# psoc63 register map
Vendor: Cypress Semiconductor; Series: psoc63; File version: 1.0
CPU: CM4 r0p1, little endian, MPU, FPU, VTOR, 3 interrupt priority bits
Registers are 32-bit, read-write, reset 0x0 unless marked. A register's access mark holds for its fields unless they carry their own. Offsets are from the block's base; [hi:lo] are bit positions; lines under a group give offsets from that group; {n}, {i} and the like mark numbered series; 'fields as' and 'values as' point back to an identical list.

## FLASHC — Flash controller
Base 0x40250000
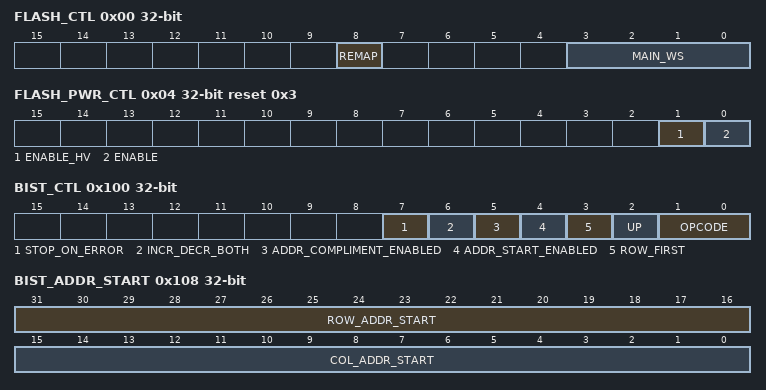
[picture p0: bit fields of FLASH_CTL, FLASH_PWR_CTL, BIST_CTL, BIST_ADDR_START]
0x00 FLASH_CTL — Control
  [8] REMAP — Specifies remapping of FLASH macro main region. '0': No remapping. '1': Remapping. The highest address bit of the FLASH main region is inverted. This effectively remaps the location of FLASH main region physical sectors in the logical address space. In other words, the higher half physical sectors are swapped with the lower half physical sectors. Note: remapping only affects reading of the FLASH main region (over the R interface). It does NOT affect programming/erasing of the FLASH memory region (over the C interface). E.g., for a 512 KB / 4 Mb main region, the logical address space ranges from [0x1000:0000, 0x1007:ffff] (the highest bit if the FLASH main region is bit 18). The memory has four physical sectors: sectors 0, 1, 2 and 3. If REMAP is '0', the physical regions logical addresses are as follows: - The physical region 0: [0x1000:0000, 0x1001:ffff]. - The physical region 1: [0x1002:0000, 0x1003:ffff]. - The physical region 2: [0x1004:0000, 0x1005:ffff]. - The physical region 3: [0x1006:0000, 0x1007:ffff]. If REMAP is '1', the physical regions logical addresses are as follows: - The physical region 0: [0x1004:0000, 0x1005:ffff]. - The physical region 1: [0x1006:0000, 0x1007:ffff]. - The physical region 2: [0x1000:0000, 0x1001:ffff]. - The physical region 3: [0x1002:0000, 0x1003:ffff]. Note: when the REMAP is changed, SW should invalidate the caches and buffers.
  [3:0] MAIN_WS — FLASH macro main interface wait states: '0': 0 wait states. ... '15': 15 wait states
0x04 FLASH_PWR_CTL reset 0x3 — Flash power control
  [1] ENABLE_HV — Controls 'enable_hv' pin of the Flash memory.
  [0] ENABLE — Controls 'enable' pin of the Flash memory.
0x08 FLASH_CMD — Command
  [0] INV — FLASH cache and buffer invalidation for ALL cache and buffers. SW writes a '1' to clear the cache and buffers. HW sets this field to '0' when the operation is completed. The operation takes a maximum of three clock cycles on the slowest of the clk_slow and clk_fast clocks. The caches' LRU structures are also reset to their default state.
0x100 BIST_CTL — BIST control
  [7] STOP_ON_ERROR — Specifies the BIST to continue indefinitely, regardless of occurrence of errors or not. '0': BIST controller doesn't stop on the data failures, it continues regardless of the errors. '1': BIST controller stops on when the first data failure is encounted.
  [6] INCR_DECR_BOTH — Specifies to generate patterns where both column address and row address are incremented/decremented simultaneously. '0': Generate normal increment/decrement patterns. '1': Generate address patterns with both row and column address changing. Example: With UP = 1 and ROW_FIRST = 0 00_00 01_01 10_10 11_11 00_01 01_10 10_11 11_00 00_10 ...
  [5] ADDR_COMPLIMENT_ENABLED — Specifies to generate address compliment patterns. '0': Generate normal increment/decrement patterns. '1': Generate address patterns which interleaves compliment of previous address in between. Example: The following is an exaple pattern, With UP=1 and ROW_FIRST =0 00_00 11_11 00_01 11_10 00_10 11_01 ...
  [4] ADDR_START_ENABLED — Specifies Flash BIST start addresses: '0': Row and column addresses start with their maximum/minimum values. '1': Row and column addresses start with their values as specified by BIST_ADDR_START. This feature is supported only for simple increment/decrement patterns. It is not supported with address compliment pattern (BIST_CTL.ADDR_COMPLIMENT_ENABLED) or address pattern which increments/decrements both row address and column address (BIST_CTL.INCR_DECR_BOTH) for every read.
  [3] ROW_FIRST — Specifies how the Flash BIST addresses are generated: '0': Column address is incremented/decremented till it reaches its maximum/minimum value. Once it reach its maximum/minimum value, it is set to its mimimum/maximum value and only then is the row address incremented/decremented. '1': Row address is incremented/decremented till it reaches its maximum/minimum value. Once it reach its maximum/minimum value, it is set to its mimimum/maximum value and only then is the column address incremented/decremented.
  [2] UP — Specifies direction in which Flash BIST steps through addresses: ''0': BIST steps through the Flash from the maximum row and column addresses (as specified by a design time configurtion parameter when ADDR_START_ENABLED is '0' and as specified by BIST_ADDR_START when ADDR_START_ENABLED is '1') to the minimum row and column addresses. '1': BIST steps through the Flash from the minimum row and column addresses ('0' when ADDR_START_ENABLED is '0' and as specified by BIST_ADDR_START when ADDR_START_ENABLED is '1') to the maximum row and column addresses.
  [1:0] OPCODE — This field specifies how the data check should be performed after reading the data from Flash memory. '0': Read the Flash and compare the output to BIST_DATA (R0). '1': Read the Flash and compare the output to the binary complement of BIST_DATA (R1). '2': Read the Flash and compare with BIST_DATA[] and compliment of BIST_DATA alternately (R01). The expected data of the first read is BIST_DATA, expected data of the second read is binary compliment of BIST_DATA, third read expected data is BIST_DATA, fourth read expected data is binary compliment of BIST_DATA and so on.
0x104 BIST_CMD — BIST command
  [0] START — 1': Start FLASH BIST. Hardware set this field to '0' when BIST is completed.
0x108 BIST_ADDR_START — BIST address start register
  [31:16] ROW_ADDR_START — Row start address. Useful to apply BIST to a part of an Flash. The value of this field should be in a legal range (a value outside of the legal range has an undefined result, and may lock up the BIST state machine). This legal range is dependent on the number of rows of the SRAM the BIST is applied to (as specified by BIST_CTL.SRAMS_ENABLED). E.g. for a Flash with m columns, the legal range is [0, m-1].
  [15:0] COL_ADDR_START — Column start address. Useful to apply BIST to a part of an Flash. The value of this field should be in a legal range (a value outside of the legal range has an undefined result, and may lock up the BIST state machine). This legal range is dependent on the number of columns of the SRAM the BIST is applied to (as specified by BIST_CTL.SRAMS_ENABLED). E.g. for a Flash with n columns, the legal range is [0, n-1].
{0x10C+4i} BIST_DATA[{i}] (i=0..7) — BIST data register(s)
  [31:0] DATA — BIST data register to store the expected value for data comparison. For a 128-bit Flash memory, there will be 4 BIST_DATA registers to store 128-bit value.
{0x12C+4i} BIST_DATA_ACT[{i}] (i=0..7) ro reset not defined — BIST data actual register(s)
  [31:0] DATA — This field specified the actual Flash data output that caused the BIST failure.
{0x14C+4i} BIST_DATA_EXP[{i}] (i=0..7) ro reset not defined — BIST data expected register(s)
  [31:0] DATA — This field specified the expected Flash data output.
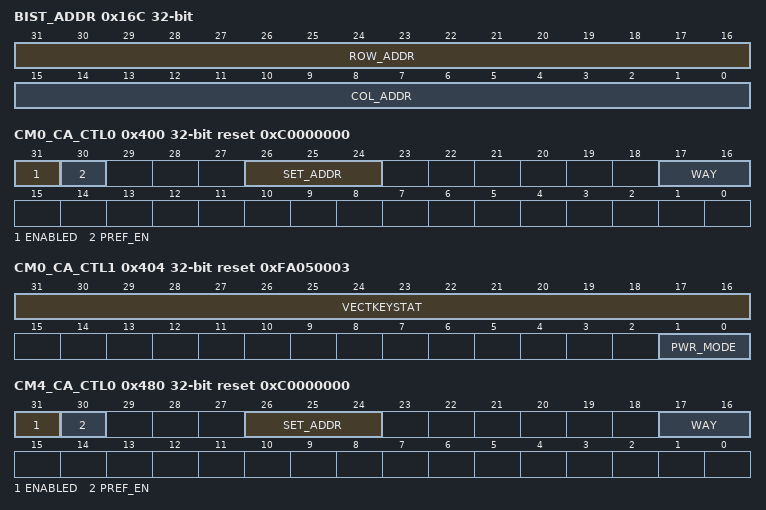
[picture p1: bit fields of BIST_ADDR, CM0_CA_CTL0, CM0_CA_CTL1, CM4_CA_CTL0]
0x16C BIST_ADDR ro reset not defined — BIST address register
  [31:16] ROW_ADDR — Current row address.
  [15:0] COL_ADDR — Current column address.
0x170 BIST_STATUS
  [0] FAIL — 0': BIST passed. '1': BIST failed.
0x400 CM0_CA_CTL0 reset 0xC0000000 — CM0+ cache control
  [31] ENABLED — Cache enable: '0': Disabled. The cache tag valid bits are reset to '0's and the cache LRU information is set to '1's (making way 0 the LRU way and way 3 the MRU way). '1': Enabled.
  [30] PREF_EN — Prefetch enable: '0': Disabled. '1': Enabled. Prefetching requires the cache to be enabled; i.e. ENABLED is '1'.
  [26:24] SET_ADDR — Specifies the cache set for which cache information is provided in CM0_CA_STATUS0/1/2.
  [17:16] WAY — Specifies the cache way for which cache information is provided in CM0_CA_STATUS0/1/2.
0x404 CM0_CA_CTL1 reset 0xFA050003 — CM0+ cache control
  [31:16] VECTKEYSTAT ro — Register key (to prevent accidental writes). - Should be written with a 0x05fa key value for the write to take effect. - Always reads as 0xfa05.
  [1:0] PWR_MODE — Set Power mode for CM0 cache
    0=OFF (See CM4_PWR_CTL); 1=RSVD (undefined); 2=RETAINED (See CM4_PWR_CTL); 3=ENABLED (See CM4_PWR_CTL)
0x408 CM0_CA_CTL2 reset 0x12C — CM0+ cache control
  [9:0] PWRUP_DELAY — Number clock cycles delay needed after power domain power up
0x40C CM0_CA_CMD — CM0+ cache command
  [0] INV — FLASH cache invalidation. SW writes a '1' to clear the cache. W sets this field to '0' when the operation is completed. The operation takes a maximum of three clock cycles on the slowest of the clk_slow and clk_fast clocks. The cache's LRU structure is also reset to its default state.
0x440 CM0_CA_STATUS0 ro — CM0+ cache status 0
  [15:0] VALID16 — Sixteen valid bits of the cache line specified by CM0_CA_CTL.WAY and CM0_CA_CTL.SET_ADDR.
0x444 CM0_CA_STATUS1 ro reset not defined — CM0+ cache status 1
  [31:0] TAG — Cache line address of the cache line specified by CM0_CA_CTL.WAY and CM0_CA_CTL.SET_ADDR.
0x448 CM0_CA_STATUS2 ro reset not defined — CM0+ cache status 2
  [5:0] LRU — Six bit LRU representation of the cache set specified by CM0_CA_CTL.SET_ADDR. The encoding of the field is as follows ('X_LRU_Y' indicates that way X is Less Recently Used than way Y): Bit 5: 0_LRU_1: way 0 less recently used than way 1. Bit 4: 0_LRU_2. Bit 3: 0_LRU_3. Bit 2: 1_LRU_2. Bit 1: 1_LRU_3. Bit 0: 2_LRU_3.
0x480 CM4_CA_CTL0 reset 0xC0000000 — CM4 cache control
  [31] ENABLED — See CM0_CA_CTL.
  [30] PREF_EN — See CM0_CA_CTL.
  [26:24] SET_ADDR — See CM0_CA_CTL.
  [17:16] WAY — See CM0_CA_CTL.
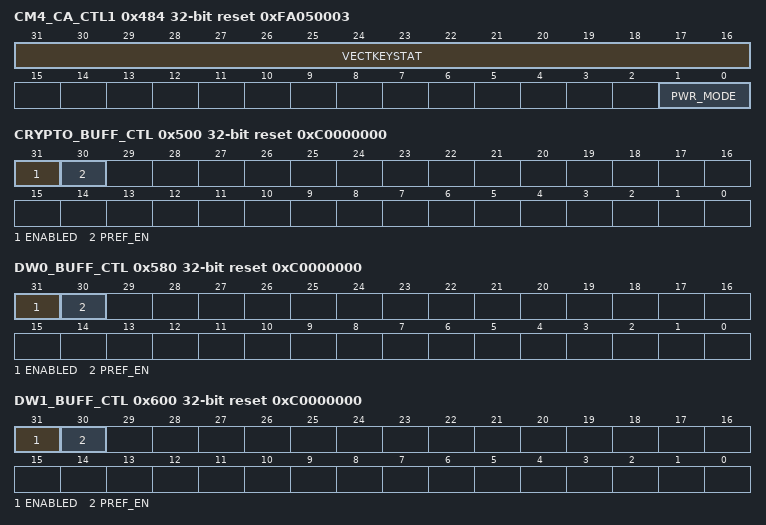
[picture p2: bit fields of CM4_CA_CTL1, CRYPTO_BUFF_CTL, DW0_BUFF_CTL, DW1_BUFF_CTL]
0x484 CM4_CA_CTL1 reset 0xFA050003 — CM4 cache control
  [31:16] VECTKEYSTAT ro — Register key (to prevent accidental writes). - Should be written with a 0x05fa key value for the write to take effect. - Always reads as 0xfa05.
  [1:0] PWR_MODE — Set Power mode for CM4 cache
    values as CM0_CA_CTL1.PWR_MODE
0x488 CM4_CA_CTL2 reset 0x12C — CM4 cache control
  fields as CM0_CA_CTL2
0x48C CM4_CA_CMD — CM4 cache command
  [0] INV — See CM0_CA_CMD.
0x4C0 CM4_CA_STATUS0 ro — CM4 cache status 0
  [15:0] VALID16 — See CM0_CA_STATUS0.
0x4C4 CM4_CA_STATUS1 ro reset not defined — CM4 cache status 1
  [31:0] TAG — See CM0_CA_STATUS1.
0x4C8 CM4_CA_STATUS2 ro reset not defined — CM4 cache status 2
  [5:0] LRU — See CM0_CA_STATUS2.
0x500 CRYPTO_BUFF_CTL reset 0xC0000000 — Cryptography buffer control
  [31] ENABLED — Cache enable: '0': Disabled. '1': Enabled.
  [30] PREF_EN — Prefetch enable: '0': Disabled. '1': Enabled. Prefetching requires the buffer to be enabled; i.e. ENABLED is '1'.
0x508 CRYPTO_BUFF_CMD — Cryptography buffer command
  [0] INV — FLASH buffer invalidation. SW writes a '1' to clear the buffer. HW sets this field to '0' when the operation is completed.
0x580 DW0_BUFF_CTL reset 0xC0000000 — Datawire 0 buffer control
  [31] ENABLED — See CRYPTO_BUFF_CTL.
  [30] PREF_EN — See CRYPTO_BUFF_CTL.
0x588 DW0_BUFF_CMD — Datawire 0 buffer command
  [0] INV — See CRYPTO_BUFF_CMD.
0x600 DW1_BUFF_CTL reset 0xC0000000 — Datawire 1 buffer control
  fields as DW0_BUFF_CTL
0x608 DW1_BUFF_CMD — Datawire 1 buffer command
  [0] INV — See CRYPTO_BUFF_CMD.
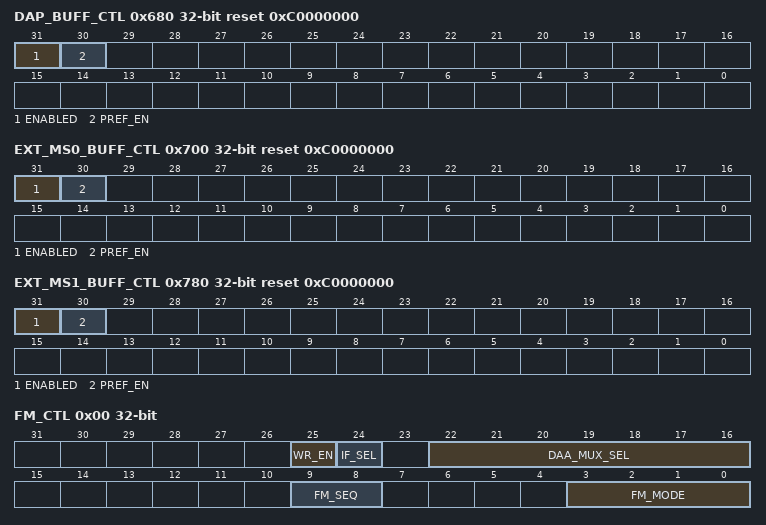
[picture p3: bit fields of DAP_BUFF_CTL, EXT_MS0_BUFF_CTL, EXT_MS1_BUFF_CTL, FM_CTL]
0x680 DAP_BUFF_CTL reset 0xC0000000 — Debug access port buffer control
  fields as DW0_BUFF_CTL
0x688 DAP_BUFF_CMD — Debug access port buffer command
  [0] INV — See CRYPTO_BUFF_CMD.
0x700 EXT_MS0_BUFF_CTL reset 0xC0000000 — External master 0 buffer control
  fields as DW0_BUFF_CTL
0x708 EXT_MS0_BUFF_CMD — External master 0 buffer command
  [0] INV — See CRYPTO_BUFF_CMD.
0x780 EXT_MS1_BUFF_CTL reset 0xC0000000 — External master 1 buffer control
  fields as DW0_BUFF_CTL
0x788 EXT_MS1_BUFF_CMD — External master 1 buffer command
  [0] INV — See CRYPTO_BUFF_CMD.
0xF000 FM_CTL group — Flash Macro Registers
  0x00 FM_CTL — Flash macro control
    [25] WR_EN — '0': normal mode '1': Fm Write Enable
    [24] IF_SEL — Interface selection. Specifies the interface that is used for flash memory read operations: '0': R interface is used (default value). In this case, the flash memory address is provided as part of the R signal interface. '1': C interface is used. In this case, the flash memory address is provided by FM_MEM_ADDR (the page address) and by the C interface access offset in the FM_MEM_DATA structure.
    [22:16] DAA_MUX_SEL — Direct memory cell access address.
    [9:8] FM_SEQ — Flash macro sequence select: '0': TBD '1': TBD '2': TBD '3': TBD
    [3:0] FM_MODE — Flash macro mode selection: '0': Normal functional mode. '1': Sets 'pre-program control bit' for soft pre-program operation of all selected SONOS cells. the control bit is cleared by the HW after any program operation. '2': Sets ... '15': TBD
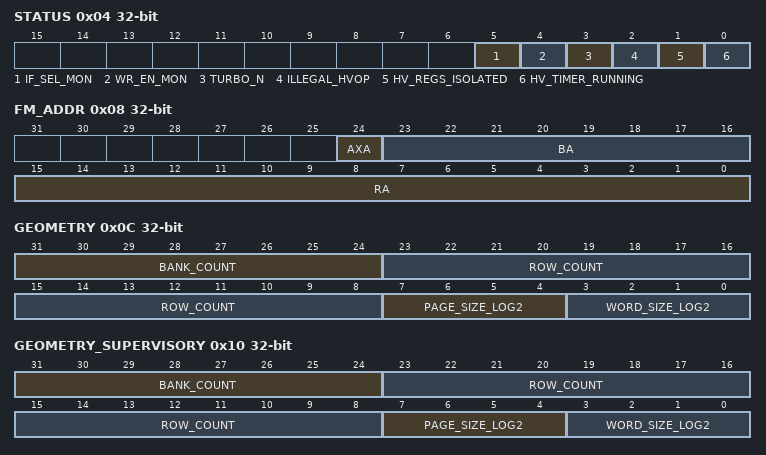
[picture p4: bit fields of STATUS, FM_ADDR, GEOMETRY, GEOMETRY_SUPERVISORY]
  0x04 STATUS ro
    [5] IF_SEL_MON — FM_CTL.IF_SEL bit after being synchronized in clk_r domain
    [4] WR_EN_MON — FM_CTL.WR_EN bit after being synchronized in clk_r domain
    [3] TURBO_N — After FM power up indicates the analog blocks currents are boosted to faster reach their functional state.. Used in the testchip boot only as an 'FM READY' flag. '0' - turbo mode '1' - normal mode
    [2] ILLEGAL_HVOP — Indicates a bulk,sector erase, program has been requested when axa=1 '0' - no error '1' - illegal HV operation error
    [1] HV_REGS_ISOLATED — Indicates the isolation status at HV trim and redundancy registers inputs '0' - Not isolated, writing permitted '1' - isolated writing disabled
    [0] HV_TIMER_RUNNING — Indicates if the high voltage timer is running: '0': not running '1': running
  0x08 FM_ADDR — Flash macro address
    [24] AXA — Auxiliairy address field: '0': regular flash memory. '1': supervisory flash memory.
    [23:16] BA — Bank address.
    [15:0] RA — Row address.
  0x0C GEOMETRY ro — Regular flash geometry
    [31:24] BANK_COUNT — Number of banks (minus 1): '0': 1 bank '1': 2 banks ... '255': 256 banks
    [23:8] ROW_COUNT — Number of rows (minus 1): '0': 1 row '1': 2 rows '2': 3 rows ... '65535': 65536 rows
    [7:4] PAGE_SIZE_LOG2 — Number of Bytes per page (log 2): '0': 1 Byte '1': 2 Bytes '2': 4 Bytes ... '15': 32768 Bytes The currently planned flash macros have a page size of either 256 Byte or 512 Byte, resulting in PAGE_SIZE_LOG2 settings of 8 and 9 respectively.
    [3:0] WORD_SIZE_LOG2 — Number of Bytes per word (log 2). A word is defined as the data that is read from the flash macro over the R interface with a single read access: '0': 1 Byte '1': 2 Bytes '2': 4 Bytes ... '7': 128 Bytes The currently planned flash macros have a word size of either 32-bit, 64-bit or 128-bit, resulting in WORD_SIZE_LOG2 settings of 2, 3 and 4 respectively.
  0x10 GEOMETRY_SUPERVISORY ro — Supervisory flash geometry
    [31:24] BANK_COUNT — Number of banks (minus 1). BANK_COUNT is less or equal to GEOMETRY.BANK_COUNT.
    [23:8] ROW_COUNT — Number of rows (minus 1). ROW_COUNT is typically less than GEOMETRY.ROW_COUNT
    [7:4] PAGE_SIZE_LOG2 — Number of Bytes per page (log 2). See GEOMETRY.PAGE_SIZE_LOG2. Typically, PAGE_SIZE_LOG2 equals GEOMETRY.PAGE_SIZE_LOG2.
    [3:0] WORD_SIZE_LOG2 — Number of Bytes per word (log 2). See GEOMETRY.WORD_SIZE_LOG2. Typically, WORD_SIZE_LOG2 equals GEOMETRY.WORD_SIZE_LOG2.
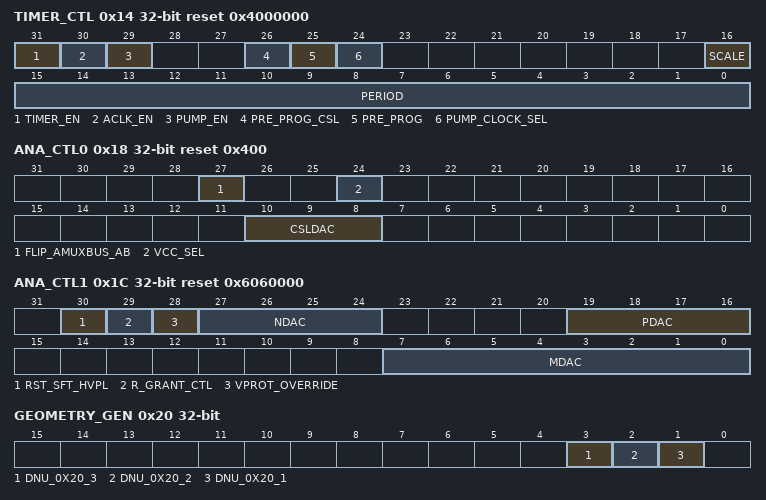
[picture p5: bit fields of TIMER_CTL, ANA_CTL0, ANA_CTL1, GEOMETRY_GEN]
  0x14 TIMER_CTL reset 0x4000000 — Timer control
    [31] TIMER_EN — Timer enable: '0': disabled '1': enabled. SW sets this field to '1' to start the timer. HW sets this field to '0' when the timer is expired.
    [30] ACLK_EN — ACLK enable (generates a single cycle pulse for the FM): '0': disabled '1': enabled. SW set this field to '1' to generate a single cycle pulse. HW sets this field to '0' when the pulse is generated.
    [29] PUMP_EN — Pump enable: '0': disabled '1': enabled (also requires FM_CTL.IF_SEL to be '1', this additional restriction is reuired to prevent non intential clearing of the FM). SW sets this field to '1' to generate a single PE pulse. HW clears this field when timer is expired.
    [26] PRE_PROG_CSL — '0' CSL lines driven by CSL_DAC '1' CSL lines driven by VNEG_G
    [25] PRE_PROG — '1' during pre-program operation
    [24] PUMP_CLOCK_SEL — Pump clock select: '0': internal clock. '1': external clock.
    [16] SCALE — Timer tick scale: '0': 1 microsecond. '1': 100 microseconds.
    [15:0] PERIOD — Timer period in either microseconds (SCALE is '0') or 100's of microseconds (SCALE is '1') multiples.
  0x18 ANA_CTL0 reset 0x400 — Analog control 0
    [27] FLIP_AMUXBUS_AB — Flips amuxbusa and amuxbusb '0': amuxbusa, amuxbusb '1': amuxbusb, amuxbusb
    [24] VCC_SEL — Vcc select: '0': 1.2 V : LP reset value '1': 0.95 V: ULP reset value Note: the flash macro compiler has a configuration option that specifies the default/reset value of this field.
    [10:8] CSLDAC — Trimming of common source line DAC.
  0x1C ANA_CTL1 reset 0x6060000 — Analog control 1
    [30] RST_SFT_HVPL — '1': Page Latches Soft Reset
    [29] R_GRANT_CTL — r_grant control: '0': r_grant normal functionality '1': forces r_grant LO synchronized on clk_r
    [28] VPROT_OVERRIDE — '0': vprot = BG.vprot. '1': vprot = vcc
    [27:24] NDAC — Trimming of negative pump output Voltage:
    [19:16] PDAC — Trimming of positive pump output Voltage:
    [7:0] MDAC — Trimming of the output margin Voltage as a function of Vpos and Vneg.
  0x20 GEOMETRY_GEN ro — N/A, DNU
    [3] DNU_0X20_3, [2] DNU_0X20_2, [1] DNU_0X20_1
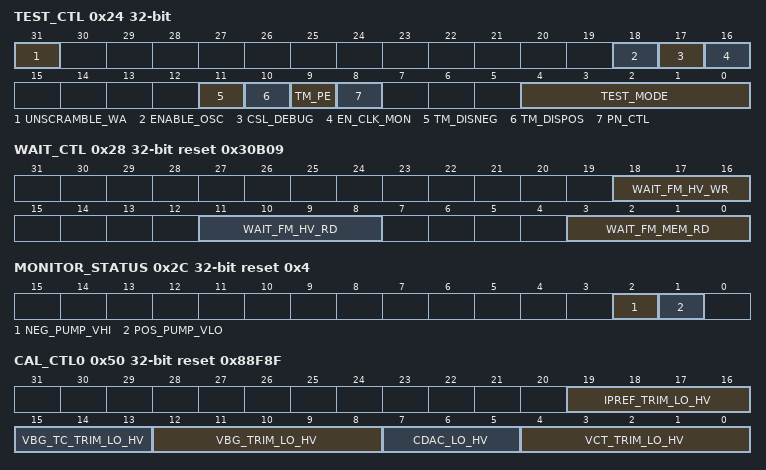
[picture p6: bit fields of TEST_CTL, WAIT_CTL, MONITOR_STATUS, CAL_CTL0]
  0x24 TEST_CTL — Test mode control
    [31] UNSCRAMBLE_WA — See BSN-242 memo '0': normal '1': disables the Word Address scrambling
    [18] ENABLE_OSC — 0': the oscillator enable logic has control over the internal oscillator '1': forces oscillator enable HI
    [17] CSL_DEBUG — Engineering Debug Register
    [16] EN_CLK_MON — 1: enables the oscillator output monitor
    [11] TM_DISNEG — Test mode negative pump disable
    [10] TM_DISPOS — Test mode positive pump disable
    [9] TM_PE — PUMP_EN override: Pump Enable =PUMP_EN | PE_TM
    [8] PN_CTL — Postive/negative margin mode control: '0': negative margin control '1': positive margin control
    [4:0] TEST_MODE — Test mode control: '0'-'31': TBD
  0x28 WAIT_CTL reset 0x30B09 — Wiat State control
    [18:16] WAIT_FM_HV_WR — Number of C interface wait cycles (on 'clk_c') for a write to the high Voltage page latches.
    [11:8] WAIT_FM_HV_RD — Number of C interface wait cycles (on 'clk_c') for a read from the high Voltage page latches. Common for reading HV Page Latches and the DATA_COMP_RESULT bit
    [3:0] WAIT_FM_MEM_RD — Number of C interface wait cycles (on 'clk_c') for a read from the memory
  0x2C MONITOR_STATUS ro reset 0x4
    [2] NEG_PUMP_VHI, [1] POS_PUMP_VLO
  0x30 SCRATCH_CTL — Scratch Control
    [31:0] DUMMY32 — Scratchpad register fields. Provided for test purposes.
  0x34 HV_CTL reset 0x32 — High voltage control
    [7:0] TIMER_CLOCK_FREQ — Specifies the frequency in MHz of the timer clock 'clk_t' as provide to the flash macro. E.g., if '4', the timer clock 'clk_t' has a frequency of 4 MHz.
  0x38 ACLK_CTL wo — Aclk control
    [0] ACLK_GEN — A write to this register generates a ACLK pulse for the flash macro (also requires FM_CTL.IF_SEL to be '1').
  0x3C INTR — Interrupt
    [0] TIMER_EXPIRED — Set to '1', when event is detected. Write INTR field with '1', to clear bit. Write INTR_SET field with '1', to set bit.
  0x40 INTR_SET — Interrupt set
    [0] TIMER_EXPIRED — Write INTR_SET field with '1' to set corresponding INTR field (a write of '0' has no effect).
  0x44 INTR_MASK — Interrupt mask
    [0] TIMER_EXPIRED — Mask for corresponding field in INTR register.
  0x48 INTR_MASKED ro — Interrupt masked
    [0] TIMER_EXPIRED — Logical and of corresponding request and mask fields.
  0x4C FM_HV_DATA_ALL wo — Flash macro high Voltage page latches data (for all page latches)
    [31:0] DATA32 — Write all high Voltage page latches with the same 32-bit data in a single write cycle
  0x50 CAL_CTL0 reset 0x88F8F — Cal control BG LO trim bits
    [19:16] IPREF_TRIM_LO_HV — LO Bandgap IPTAT trim control.
    [15:13] VBG_TC_TRIM_LO_HV — LO Bandgap Voltage Temperature Compensation trim control
    [12:8] VBG_TRIM_LO_HV — LO Bandgap Voltage trim control.
    [7:5] CDAC_LO_HV — LO Temperature compensated trim DAC. To control Vcstat slope for Vpos.
    [4:0] VCT_TRIM_LO_HV — LO Bandgap Voltage Temperature Compensation trim control.
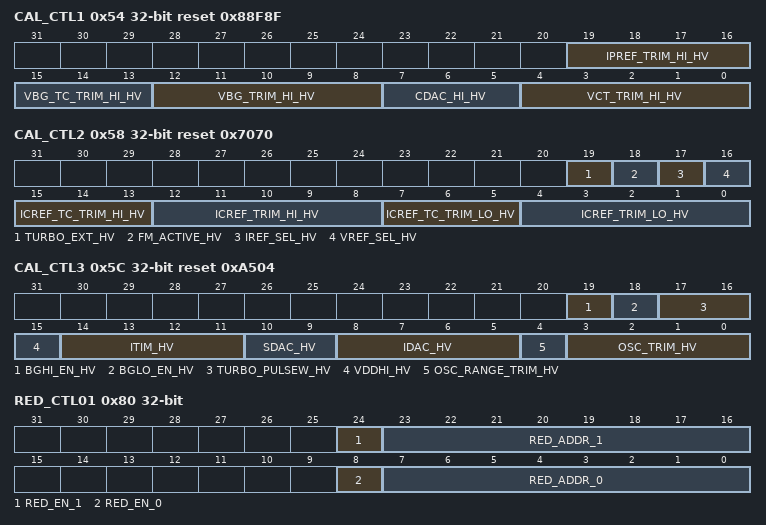
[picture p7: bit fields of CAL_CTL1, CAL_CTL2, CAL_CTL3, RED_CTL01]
  0x54 CAL_CTL1 reset 0x88F8F — Cal control BG HI trim bits
    [19:16] IPREF_TRIM_HI_HV — HI Bandgap IPTAT trim control.
    [15:13] VBG_TC_TRIM_HI_HV — HI Bandgap Voltage Temperature Compensation trim control.
    [12:8] VBG_TRIM_HI_HV — HI Bandgap Voltage trim control.
    [7:5] CDAC_HI_HV — HI Temperature compensated trim DAC. To control Vcstat slope for Vpos.
    [4:0] VCT_TRIM_HI_HV — HI Bandgap Voltage Temperature Compensation trim control.
  0x58 CAL_CTL2 reset 0x7070 — Cal control BG LO&HI ipref trim, ref sel, fm_active, turbo_ext
    [19] TURBO_EXT_HV — 0: turbo signal generated internally 1: turbo cleared by clk_pump_ext HI
    [18] FM_ACTIVE_HV — 0: No Action 1: Forces FM SYS in active mode
    [17] IREF_SEL_HV — Current reference: '0': internal current reference '1': external current reference
    [16] VREF_SEL_HV — Voltage reference: '0': internal bandgap reference '1': external voltage reference
    [15:13] ICREF_TC_TRIM_HI_HV — HI Bandgap Current Temperature Compensation trim control.
    [12:8] ICREF_TRIM_HI_HV — HI Bandgap Current trim control.
    [7:5] ICREF_TC_TRIM_LO_HV — LO Bandgap Current Temperature Compensation trim control
    [4:0] ICREF_TRIM_LO_HV — LO Bandgap Current trim control.
  0x5C CAL_CTL3 reset 0xA504 — Cal control osc trim bits, idac, sdac, itim, bdac.
    [19] BGHI_EN_HV — HI Bandgap Enable
    [18] BGLO_EN_HV — LO Bandgap Enable
    [17:16] TURBO_PULSEW_HV — Turbo pulse width trim
    [15] VDDHI_HV — 0': vdd<2.3V '1': vdd>=2.3V
    [14:11] ITIM_HV — Trimming of timing current
    [10:9] SDAC_HV
    [8:5] IDAC_HV
    [4] OSC_RANGE_TRIM_HV — 0: Oscillator High Frequency Range 1: Oscillator Low Frequency range
    [3:0] OSC_TRIM_HV — Flash macro pump clock trim control.
  0x60 BOOKMARK wo — Bookmark register - keeps the current FW HV seq
    [31:0] BOOKMARK — Used by FW. Keeps the Current HV cycle sequence
  0x80 RED_CTL01 — Redundancy Control normal sectors 0,1
    [24] RED_EN_1 — '1': Redundancy Enable for Sector 1
    [23:16] RED_ADDR_1 — Bad Row Pair Address for Sector 1
    [8] RED_EN_0 — '1': Redundancy Enable for Sector 0
    [7:0] RED_ADDR_0 — Bad Row Pair Address for Sector 0
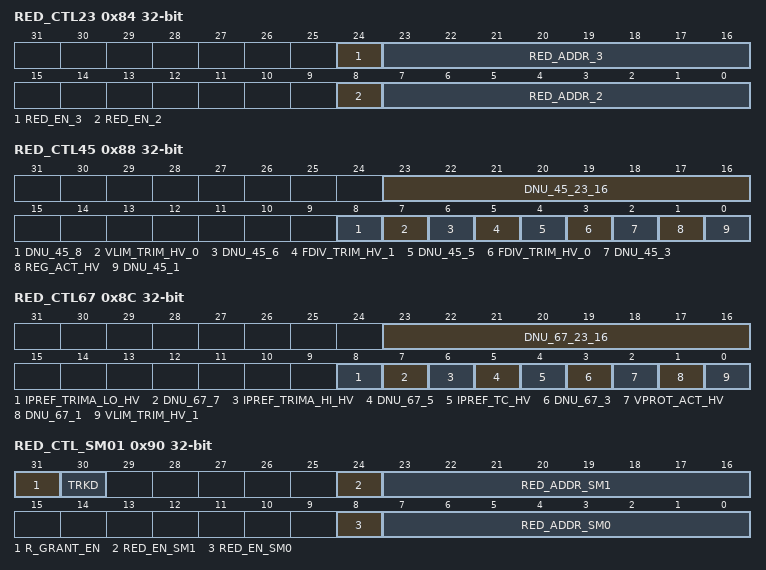
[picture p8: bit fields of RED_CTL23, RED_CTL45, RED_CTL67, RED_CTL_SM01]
  0x84 RED_CTL23 — Redundancy Controll normal sectors 2,3
    [24] RED_EN_3 — 1': Redundancy Enable for Sector 3
    [23:16] RED_ADDR_3 — Bad Row Pair Address for Sector 3
    [8] RED_EN_2 — 1': Redundancy Enable for Sector 2
    [7:0] RED_ADDR_2 — Bad Row Pair Address for Sector 2
  0x88 RED_CTL45 — Redundancy Controll normal sectors 4,5
    [23:16] DNU_45_23_16 — Not Used
    [8] DNU_45_8 — Not Used
    [7] VLIM_TRIM_HV_0 — '2b00' V2 = 650mV see vlim_trim_hv<1> value as well '2b01' V2 = 600mV '2b10' V2 = 750mV '2b11' V2 = 700mV
    [6] DNU_45_6 — Not Used
    [5] FDIV_TRIM_HV_1 — '2b00' F = 1MHz see fdiv_trim_hv<0> value as well '2b01' F = 0.5MHz '2b10' F = 2MHz '2b11' F = 4Mhz
    [4] DNU_45_5 — Not Used
    [3] FDIV_TRIM_HV_0 — '2b00' F = 1MHz see fdiv_trim_hv<1> value as well '2b01' F = 0.5MHz '2b10' F = 2MHz '2b11' F = 4Mhz
    [2] DNU_45_3 — Not Used
    [1] REG_ACT_HV — Forces the VBST regulator in active mode all the time
    [0] DNU_45_1 — Not Used
  0x8C RED_CTL67 — Redundancy Controll normal sectors 6,7
    [23:16] DNU_67_23_16 — Not Used
    [8] IPREF_TRIMA_LO_HV — Adds 200-300nA boost on IPREF_LO
    [7] DNU_67_7 — Not Used
    [6] IPREF_TRIMA_HI_HV — Adds 200-300nA boost on IPREF_HI
    [5] DNU_67_5 — Not Used
    [4] IPREF_TC_HV — Reduces the IPREF Tempco by not subtracting ICREF form IPREF - IPREF will be 1uA
    [3] DNU_67_3 — Not Used
    [2] VPROT_ACT_HV — Forces VPROT in active mode all the time
    [1] DNU_67_1 — Not Used
    [0] VLIM_TRIM_HV_1 — '2b00' V2 = 650mV see vlim_trim_hv<0> value as well '2b01' V2 = 600mV '2b10' V2 = 750mV '2b11' V2 = 700mV
  0x90 RED_CTL_SM01 — Redundancy Controll special sectors 0,1
    [31] R_GRANT_EN — '0': r_grant handshake disabled, r_grant always 1. '1': r_grand handshake enabled
    [30] TRKD — Sense Amp Control tracking delay
    [24] RED_EN_SM1 — Redundancy Enable for Special Sector 1
    [23:16] RED_ADDR_SM1 — Bad Row Pair Address for Special Sector 1
    [8] RED_EN_SM0 — Redundancy Enable for Special Sector 0
    [7:0] RED_ADDR_SM0 — Bad Row Pair Address for Special Sector 0
  {0x100+4j} TM_CMPR[{j}] (j=0..31) ro — Do Not Use
    [0] DATA_COMP_RESULT — The result of a comparison between the flash macro data output and the content of the high voltage page latches. The comparison result for a given column 'Column_Number' is updated in this register field on a read to address: 0x100+4*Column_Number. The number of wait states is given by WAIT_CTL.WAIT_FM_HV_RD. '0': FALSE (not equal) '1': TRUE (equal)
  {0x800+4j} FM_HV_DATA[{j}] (j=0..255) — Flash macro high Voltage page latches data
    [31:0] DATA32 — Four page latch Bytes (when writing to the page latches, it also requires FM_CTL.IF_SEL to be '1'). Note: the high Voltage page latches are readable for test mode functionality.
  {0xC00+4j} FM_MEM_DATA[{j}] (j=0..255) ro — Flash macro memory sense amplifier and column decoder data
    [31:0] DATA32 — Sense amplifier and cloumn multiplexer structure Bytes. The read data is dependent on FM_CTL.IF_SEL: - IF_SEL is '0': data as specified by the R interface address - IF_SEL is '1': data as specified by FM_MEM_ADDR and the offset of the accessed FM_MEM_DATA register.

## Notices in the file
Copyright 2016-2018, Cypress Semiconductor Corporation.  All rights reserved.
You may use this file only in accordance with the license, terms, conditions,
disclaimers, and limitations in the end user license agreement accompanying
the software package with which this file was provided.
